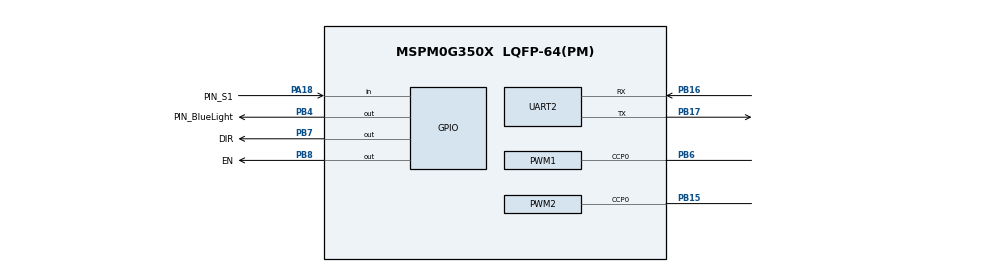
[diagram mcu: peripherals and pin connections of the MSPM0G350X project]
/**
 * @cliArgs --device "MSPM0G350X" --part "Default" --package "LQFP-64(PM)" --product "mspm0_sdk@2.05.00.05"
 * @versions {"tool":"1.24.0+4110"}
 */

/**
 * Import the modules used in this configuration.
 */
const GPIO    = scripting.addModule("/ti/driverlib/GPIO", {}, false);
const GPIO1   = GPIO.addInstance();
const GPIO2   = GPIO.addInstance();
const GPIO3   = GPIO.addInstance();
const GPIO4   = GPIO.addInstance();
const PWM     = scripting.addModule("/ti/driverlib/PWM", {}, false);
const PWM1    = PWM.addInstance();
const PWM2    = PWM.addInstance();
const SYSCTL  = scripting.addModule("/ti/driverlib/SYSCTL");
const SYSTICK = scripting.addModule("/ti/driverlib/SYSTICK");
const TIMER   = scripting.addModule("/ti/driverlib/TIMER", {}, false);
const TIMER1  = TIMER.addInstance();
const UART    = scripting.addModule("/ti/driverlib/UART", {}, false);
const UART1   = UART.addInstance();
const UART2   = UART.addInstance();

/**
 * Write custom configuration values to the imported modules.
 */
const divider6       = system.clockTree["PLL_CLK2X_DIV"];
divider6.divideValue = 4;

const divider7       = system.clockTree["PLL_PDIV"];
divider7.divideValue = 2;

const divider9       = system.clockTree["UDIV"];
divider9.divideValue = 2;

const gate7  = system.clockTree["MFCLKGATE"];
gate7.enable = true;

const gate8  = system.clockTree["MFPCLKGATE"];
gate8.enable = true;

const multiplier2         = system.clockTree["PLL_QDIV"];
multiplier2.multiplyValue = 10;

const mux4       = system.clockTree["EXHFMUX"];
mux4.inputSelect = "EXHFMUX_XTAL";

const mux8       = system.clockTree["HSCLKMUX"];
mux8.inputSelect = "HSCLKMUX_SYSPLL2X";

const pinFunction4     = system.clockTree["HFXT"];
pinFunction4.enable    = true;
pinFunction4.inputFreq = 4;

GPIO1.$name                              = "GPIO_BUTTON";
GPIO1.associatedPins.create(2);
GPIO1.associatedPins[0].$name            = "PIN_S2";
GPIO1.associatedPins[0].direction        = "INPUT";
GPIO1.associatedPins[0].assignedPort     = "PORTB";
GPIO1.associatedPins[0].assignedPin      = "21";
GPIO1.associatedPins[0].internalResistor = "PULL_UP";
GPIO1.associatedPins[1].$name            = "PIN_S1";
GPIO1.associatedPins[1].direction        = "INPUT";
GPIO1.associatedPins[1].internalResistor = "PULL_DOWN";
GPIO1.associatedPins[1].pin.$assign      = "PA18";

const Board = scripting.addModule("/ti/driverlib/Board", {}, false);

GPIO2.$name                          = "GPIO_LED";
GPIO2.associatedPins[0].initialValue = "SET";
GPIO2.associatedPins[0].assignedPort = "PORTA";
GPIO2.associatedPins[0].assignedPin  = "0";
GPIO2.associatedPins[0].$name        = "PIN_LED";

GPIO3.$name                         = "GPIO_dizuo";
GPIO3.associatedPins.create(2);
GPIO3.associatedPins[0].$name       = "EN";
GPIO3.associatedPins[0].pin.$assign = "PB8";
GPIO3.associatedPins[1].$name       = "DIR";
GPIO3.associatedPins[1].pin.$assign = "PB7";

GPIO4.$name                              = "GPIO_BlueLight";
GPIO4.associatedPins[0].internalResistor = "PULL_DOWN";
GPIO4.associatedPins[0].$name            = "PIN_BlueLight";
GPIO4.associatedPins[0].pin.$assign      = "PB4";

PWM1.$name                              = "PWM_dizuo";
PWM1.ccIndex                            = [0];
PWM1.clockPrescale                      = 100;
PWM1.timerCount                         = 8000;
PWM1.PWM_CHANNEL_0.$name                = "ti_driverlib_pwm_PWMTimerCC2";
PWM1.ccp0PinConfig.direction            = scripting.forceWrite("OUTPUT");
PWM1.ccp0PinConfig.hideOutputInversion  = scripting.forceWrite(false);
PWM1.ccp0PinConfig.onlyInternalResistor = scripting.forceWrite(false);
PWM1.ccp0PinConfig.passedPeripheralType = scripting.forceWrite("Digital");
PWM1.ccp0PinConfig.$name                = "ti_driverlib_gpio_GPIOPinGeneric9";
PWM1.peripheral.ccp0Pin.$assign         = "PB6";

PWM2.$name                              = "PWM_biyao";
PWM2.timerCount                         = 8000;
PWM2.ccIndex                            = [0];
PWM2.clockPrescale                      = 200;
PWM2.PWM_CHANNEL_0.$name                = "ti_driverlib_pwm_PWMTimerCC3";
PWM2.ccp0PinConfig.direction            = scripting.forceWrite("OUTPUT");
PWM2.ccp0PinConfig.hideOutputInversion  = scripting.forceWrite(false);
PWM2.ccp0PinConfig.onlyInternalResistor = scripting.forceWrite(false);
PWM2.ccp0PinConfig.passedPeripheralType = scripting.forceWrite("Digital");
PWM2.ccp0PinConfig.$name                = "ti_driverlib_gpio_GPIOPinGeneric10";
PWM2.peripheral.ccp0Pin.$assign         = "PB15";

SYSCTL.forceDefaultClkConfig = true;
SYSCTL.clockTreeEn           = true;
scripting.suppress("For best practices when the CPUCLK is running at 32MHz and above, clear the flash status bit using DL_FlashCTL_executeClearStatus\\(\\) before executing any flash operation\\. Otherwise there may be false positives\\.", SYSCTL);

SYSTICK.periodEnable  = true;
SYSTICK.systickEnable = true;
SYSTICK.period        = 80;

TIMER1.$name              = "TIMER_0";
TIMER1.timerMode          = "PERIODIC";
TIMER1.timerClkPrescale   = 200;
TIMER1.interrupts         = ["ZERO"];
TIMER1.timerPeriod        = "10 ms";
TIMER1.peripheral.$assign = "TIMG0";

UART1.$name                            = "UART_WIT";
UART1.targetBaudRate                   = 115200;
UART1.direction                        = "RX";
UART1.enableFIFO                       = true;
UART1.rxTimeoutValue                   = 1;
UART1.enabledInterrupts                = ["RX_TIMEOUT_ERROR"];
UART1.enabledDMARXTriggers             = "DL_UART_DMA_INTERRUPT_RX";
UART1.rxPinConfig.hideOutputInversion  = scripting.forceWrite(false);
UART1.rxPinConfig.onlyInternalResistor = scripting.forceWrite(false);
UART1.rxPinConfig.passedPeripheralType = scripting.forceWrite("Digital");
UART1.rxPinConfig.$name                = "ti_driverlib_gpio_GPIOPinGeneric1";
UART1.peripheral.$assign               = "UART3";
UART1.DMA_CHANNEL_RX.$name             = "DMA_WIT";
UART1.DMA_CHANNEL_RX.addressMode       = "f2b";
UART1.DMA_CHANNEL_RX.srcLength         = "BYTE";
UART1.DMA_CHANNEL_RX.dstLength         = "BYTE";

UART2.$name                            = "UART_K230";
UART2.enabledInterrupts                = ["RX"];
UART2.peripheral.$assign               = "UART2";
UART2.peripheral.rxPin.$assign         = "PB16";
UART2.peripheral.txPin.$assign         = "PB17";
UART2.txPinConfig.direction            = scripting.forceWrite("OUTPUT");
UART2.txPinConfig.hideOutputInversion  = scripting.forceWrite(false);
UART2.txPinConfig.onlyInternalResistor = scripting.forceWrite(false);
UART2.txPinConfig.passedPeripheralType = scripting.forceWrite("Digital");
UART2.txPinConfig.$name                = "ti_driverlib_gpio_GPIOPinGeneric7";
UART2.rxPinConfig.hideOutputInversion  = scripting.forceWrite(false);
UART2.rxPinConfig.onlyInternalResistor = scripting.forceWrite(false);
UART2.rxPinConfig.passedPeripheralType = scripting.forceWrite("Digital");
UART2.rxPinConfig.$name                = "ti_driverlib_gpio_GPIOPinGeneric8";

/**
 * Pinmux solution for unlocked pins/peripherals. This ensures that minor changes to the automatic solver in a future
 * version of the tool will not impact the pinmux you originally saw.  These lines can be completely deleted in order to
 * re-solve from scratch.
 */
pinFunction4.peripheral.$suggestSolution           = "SYSCTL";
pinFunction4.peripheral.hfxInPin.$suggestSolution  = "PA5";
pinFunction4.peripheral.hfxOutPin.$suggestSolution = "PA6";
GPIO1.associatedPins[0].pin.$suggestSolution       = "PB21";
Board.peripheral.$suggestSolution                  = "DEBUGSS";
Board.peripheral.swclkPin.$suggestSolution         = "PA20";
Board.peripheral.swdioPin.$suggestSolution         = "PA19";
GPIO2.associatedPins[0].pin.$suggestSolution       = "PA0";
PWM1.peripheral.$suggestSolution                   = "TIMG6";
PWM2.peripheral.$suggestSolution                   = "TIMG7";
UART1.peripheral.rxPin.$suggestSolution            = "PA13";
UART1.DMA_CHANNEL_RX.peripheral.$suggestSolution   = "DMA_CH0";
